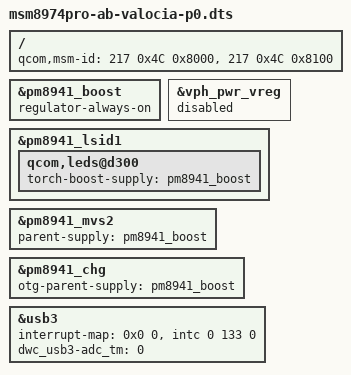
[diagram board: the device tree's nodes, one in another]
/* Copyright (c) 2013 Motorola Mobility LLC
 *
 * This program is free software; you can redistribute it and/or modify
 * it under the terms of the GNU General Public License version 2 and
 * only version 2 as published by the Free Software Foundation.
 *
 * This program is distributed in the hope that it will be useful,
 * but WITHOUT ANY WARRANTY; without even the implied warranty of
 * MERCHANTABILITY or FITNESS FOR A PARTICULAR PURPOSE.  See the
 * GNU General Public License for more details.
 */

/dts-v1/;
/include/ "msm8974pro-ab-moto-common.dtsi"
/include/ "msm8974pro-valocia-common.dtsi"


/ {
	qcom,msm-id = <217 0x4C 0x8000>, <217 0x4C 0x8100>;
};

&pm8941_boost {
	status = "okay";
	regulator-always-on;
};

&vph_pwr_vreg {
	status = "disabled";
};

&pm8941_lsid1 {
	qcom,leds@d300 {
		torch-boost-supply = <&pm8941_boost>;
	};
};

&pm8941_mvs2 {
	parent-supply = <&pm8941_boost>;
};

&pm8941_chg {
	otg-parent-supply = <&pm8941_boost>;
};

&usb3 {
        interrupt-map = <0x0 0 &intc 0 133 0>;
        interrupt-names = "hs_phy_irq";
        dwc_usb3-adc_tm = <0>;
};
